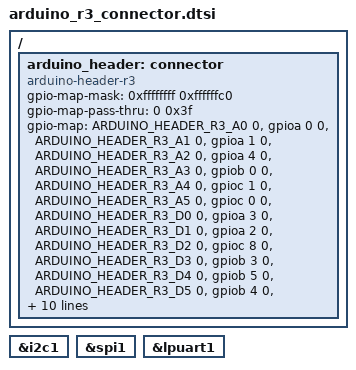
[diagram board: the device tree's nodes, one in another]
/*
 * Copyright (c) 2021 Linaro Limited
 *
 * SPDX-License-Identifier: Apache-2.0
 */

#include <zephyr/dt-bindings/gpio/arduino-header-r3.h>

/ {
	arduino_header: connector {
		compatible = "arduino-header-r3";
		#gpio-cells = <2>;
		gpio-map-mask = <0xffffffff 0xffffffc0>;
		gpio-map-pass-thru = <0 0x3f>;
		gpio-map = <ARDUINO_HEADER_R3_A0 0 &gpioa 0 0>,	/* A0 */	/* PA0 */	/* UM3062, Table 14 */
			   <ARDUINO_HEADER_R3_A1 0 &gpioa 1 0>,     /* A1 */	/* PA1 */
			   <ARDUINO_HEADER_R3_A2 0 &gpioa 4 0>,     /* A2 */	/* PA4 */
			   <ARDUINO_HEADER_R3_A3 0 &gpiob 0 0>,     /* A3 */	/* PB0 */
			   <ARDUINO_HEADER_R3_A4 0 &gpioc 1 0>,     /* A4 */	/* PC1 */
			   <ARDUINO_HEADER_R3_A5 0 &gpioc 0 0>,     /* A5 */	/* PC0 */
			   <ARDUINO_HEADER_R3_D0 0 &gpioa 3 0>,     /* D0 */	/* PA3 */	/* UM3062, Table 15 */
			   <ARDUINO_HEADER_R3_D1 0 &gpioa 2 0>,     /* D1 */	/* PA2 */
			   <ARDUINO_HEADER_R3_D2 0 &gpioc 8 0>,     /* D2 */	/* PC8 */
			   <ARDUINO_HEADER_R3_D3 0 &gpiob 3 0>,     /* D3 */	/* PB3 */
			   <ARDUINO_HEADER_R3_D4 0 &gpiob 5 0>,     /* D4 */	/* PB5 */
			   <ARDUINO_HEADER_R3_D5 0 &gpiob 4 0>,     /* D5 */	/* PB4 */
			   <ARDUINO_HEADER_R3_D6 0 &gpiob 10 0>,    /* D6 */	/* PB10 */
			   <ARDUINO_HEADER_R3_D7 0 &gpioa 8 0>,     /* D7 */	/* PA8 */
			   <ARDUINO_HEADER_R3_D8 0 &gpioc 7 0>,     /* D8 */	/* PC7 */	/* UM3062, Table 16 */
			   <ARDUINO_HEADER_R3_D9 0 &gpioc 6 0>,     /* D9 */	/* PC6 */
			   <ARDUINO_HEADER_R3_D10 0 &gpioc 9 0>,	/* D10 */	/* PC9 */
			   <ARDUINO_HEADER_R3_D11 0 &gpioa 7 0>,	/* D11 */	/* PA7 */
			   <ARDUINO_HEADER_R3_D12 0 &gpioa 6 0>,	/* D12 */	/* PA6 */
			   <ARDUINO_HEADER_R3_D13 0 &gpioa 5 0>,	/* D13 */	/* PA5 */
			   <ARDUINO_HEADER_R3_D14 0 &gpiob 7 0>,	/* D14 */	/* PB7 */
			   <ARDUINO_HEADER_R3_D15 0 &gpiob 6 0>;	/* D15 */	/* PB6 */
	};
};

arduino_i2c: &i2c1 {};

arduino_spi: &spi1 {};

arduino_serial: &lpuart1 {};
